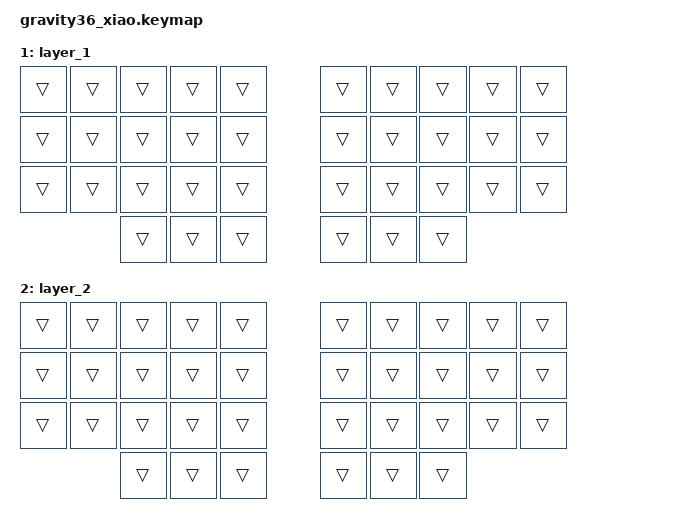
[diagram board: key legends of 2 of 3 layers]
#include <behaviors.dtsi>
#include <dt-bindings/zmk/keys.h>

/ {
    keymap {
        compatible = "zmk,keymap";
        default_layer {
            bindings = <
            /* 左手 */                                          /* 右手 */
            &kp Q   &kp W   &kp E   &kp R   &kp T       &kp Y   &kp U   &kp I   &kp O   &kp P
            &kp A   &kp S   &kp D   &kp F   &kp G       &kp H   &kp J   &kp K   &kp L   &kp SCLN
            &kp Z   &kp X   &kp C   &kp V   &kp B       &kp N   &kp M   &kp CMMA&kp DOT &kp FSLH
            
            /* 4行目：SPACEホールドでLayer1 / ENTERホールドでLayer2 */
            /*        &kp LALT &lt 1 SPC &kp INT_MUHENKAN   &kp INT_HENKAN &lt 2 RET &kp RCTRL    */

            /*    debug用    */
            &kp N1  &kp N2  &kp N3  &kp N4  &kp N5      &kp N6  &kp N7  &kp N8  &kp N9  &kp N0
            >;
        };

        // レイヤー1: SPACE長押し時に有効化（数字や記号など）
        layer_1 {
            bindings = <
            &trans  &trans  &trans  &trans  &trans      &trans  &trans  &trans  &trans  &trans
            &trans  &trans  &trans  &trans  &trans      &trans  &trans  &trans  &trans  &trans
            &trans  &trans  &trans  &trans  &trans      &trans  &trans  &trans  &trans  &trans
                    &trans  &trans  &trans              &trans  &trans  &trans
            >;
        };

        // レイヤー2: ENTER長押し時に有効化（ナビゲーションやファンクションなど）
        layer_2 {
            bindings = <
            &trans  &trans  &trans  &trans  &trans      &trans  &trans  &trans  &trans  &trans
            &trans  &trans  &trans  &trans  &trans      &trans  &trans  &trans  &trans  &trans
            &trans  &trans  &trans  &trans  &trans      &trans  &trans  &trans  &trans  &trans
                    &trans  &trans  &trans              &trans  &trans  &trans
            >;
        };
    };
};
